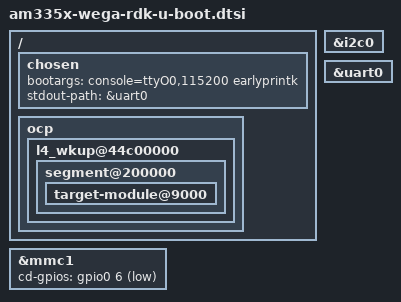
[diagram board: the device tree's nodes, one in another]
// SPDX-License-Identifier: GPL-2.0
/*
 * Copyright (C) 2019 DENX Software Engineering GmbH
 */

#include "am33xx-u-boot.dtsi"

/ {
	chosen {
		#address-cells = <1>;
		#size-cells = <1>;

		bootargs = "console=ttyO0,115200 earlyprintk";
		stdout-path = &uart0;
	};

	ocp {
		u-boot,dm-all;

		l4_wkup@44c00000 {
			u-boot,dm-all;

			segment@200000 {
				u-boot,dm-all;

				target-module@9000 {
					u-boot,dm-all;
				};
			};
		};
	};
};

&i2c0 {
	u-boot,dm-all;
};

&uart0 {
	u-boot,dm-all;
};

&mmc1 {
	u-boot,dm-all;
	cd-gpios = <&gpio0 6 GPIO_ACTIVE_LOW>;
};
